# ISD91200B_v1 register map
File version: 1.0
Registers are 32-bit, read-write, reset 0x0 unless marked. A register's access mark holds for its fields unless they carry their own. Offsets are from the block's base; [hi:lo] are bit positions; {n}, {i} and the like mark numbered series; 'fields as' and 'values as' point back to an identical list.

## PDMA_GCR — PDMA Register Map
Base 0x50008F00
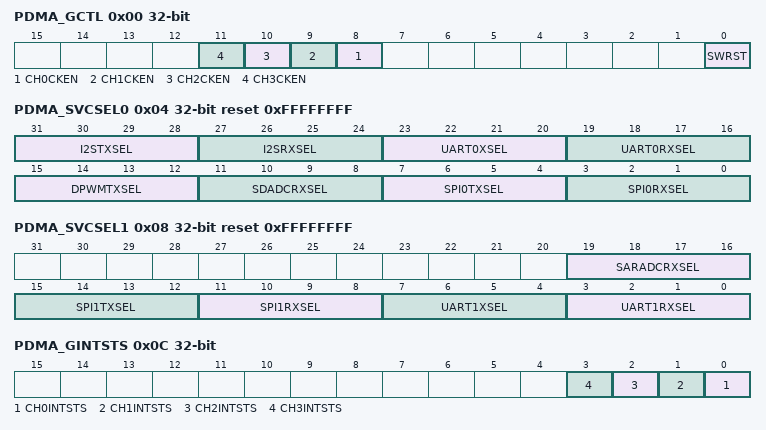
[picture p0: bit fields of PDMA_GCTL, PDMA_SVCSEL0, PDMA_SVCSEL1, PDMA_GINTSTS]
0x00 PDMA_GCTL — PDMA Global Control Register
  [n+8] CH{n}CKEN (n=0..3) — PDMA Controller Channel {n} Clock Enable Control. 1: Enable Channel {n} clock. 0: Disable Channel {n} clock.
  [0] SWRST — PDMA Software Reset. Note: This bit can reset all channels (global reset).
    0=Writing 0 to this bit has no effect; 1=Writing 1 to this bit will reset the internal state machine and pointers. The contents of control register will not be cleared. This bit will auto clear after several clock cycles
0x04 PDMA_SVCSEL0 reset 0xFFFFFFFF — PDMA Service Selection Control Register 0
  [31:28] I2STXSEL — PDMA I2S Transmit Selection. This field defines which PDMA channel is connected to I2S peripheral transmit (PDMA destination) request.
  [27:24] I2SRXSEL — PDMA I2S Receive Selection. This field defines which PDMA channel is connected to I2S peripheral receive (PDMA source) request.
  [23:20] UART0XSEL — PDMA UART0 Transmit Selection. This field defines which PDMA channel is connected to UART0 peripheral transmit (PDMA destination) request.
  [19:16] UART0RXSEL — PDMA UART0 Receive Selection. This field defines which PDMA channel is connected to UART0 peripheral receive (PDMA source) request.
  [15:12] DPWMTXSEL — PDMA DPWM Transmit Selection. This field defines which PDMA channel is connected to DPWM peripheral transmit (PDMA destination) request.
  [11:8] SDADCRXSEL — PDMA SDADC Receive Selection. This field defines which PDMA channel is connected to SDADC peripheral receive (PDMA source) request.
  [7:4] SPI0TXSEL — PDMA SPI0 Transmit Selection. This field defines which PDMA channel is connected to SPI0 peripheral transmit (PDMA destination) request.
  [3:0] SPI0RXSEL — PDMA SPI0 Receive Selection. This field defines which PDMA channel is connected to SPI0 peripheral receive (PDMA source) request.
0x08 PDMA_SVCSEL1 reset 0xFFFFFFFF — PDMA Service Selection Control Register 1
  [19:16] SARADCRXSEL — PDMA SARADC Receive Selection. This field defines which PDMA channel is connected to SARADC peripheral receive (PDMA source) request.
  [15:12] SPI1TXSEL — PDMA SPI1 Transmit Selection. This field defines which PDMA channel is connected to SPI1 peripheral transmit (PDMA destination) request.
  [11:8] SPI1RXSEL — PDMA SPI1 Receive Selection. This field defines which PDMA channel is connected to SPI1 peripheral receive (PDMA source) request.
  [7:4] UART1XSEL — PDMA UART1 Transmit Selection. This field defines which PDMA channel is connected to UART1 peripheral transmit (PDMA destination) request.
  [3:0] UART1RXSEL — PDMA UART1 Receive Selection. This field defines which PDMA channel is connected to UART1 peripheral receive (PDMA source) request.
0x0C PDMA_GINTSTS ro — PDMA Global Interrupt Status Register
  [n] CH{n}INTSTS (n=0..3) — Interrupt Pin Status of Channel {n} (Read Only). This bit is the interrupt pin status of PDMA channel {n}.

## VOLCTRL — VOLCTRL Register Map
Base 0x400B00A0
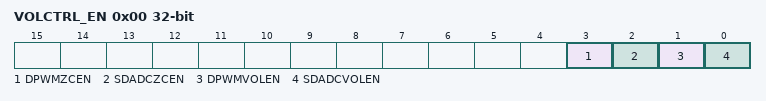
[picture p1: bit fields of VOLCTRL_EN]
0x00 VOLCTRL_EN — Volume Control Enable Register
  [3] DPWMZCEN — DPWM Audio Signal Volume Zero Crossing Enable
    0=disable zero crossing update gain; 1=enable Zero crossing update gain
  [2] SDADCZCEN — Delta-Sigma ADC Signal Volume Zero Crossing Enable
    values as DPWMZCEN
  [1] DPWMVOLEN — DPWM Audio Signal Volume Control Enable
    0=bypass the volume control function; 1=enable the volume control function
  [0] SDADCVOLEN — Delta-Sigma ADC Signal Volume Control Enable
    values as DPWMVOLEN
0x04 VOLCTRL_ADCVAL reset 0x40000 — ADC Volume Control Value
  [23:0] VALUE — Delta-Sigma ADC Signal Volume Control Value
0x08 VOLCTRL_DPWMVAL reset 0x40000 — DPWM Volume Control Value
  [23:0] VALUE — DPWM Audio Signal Volume Control Value
